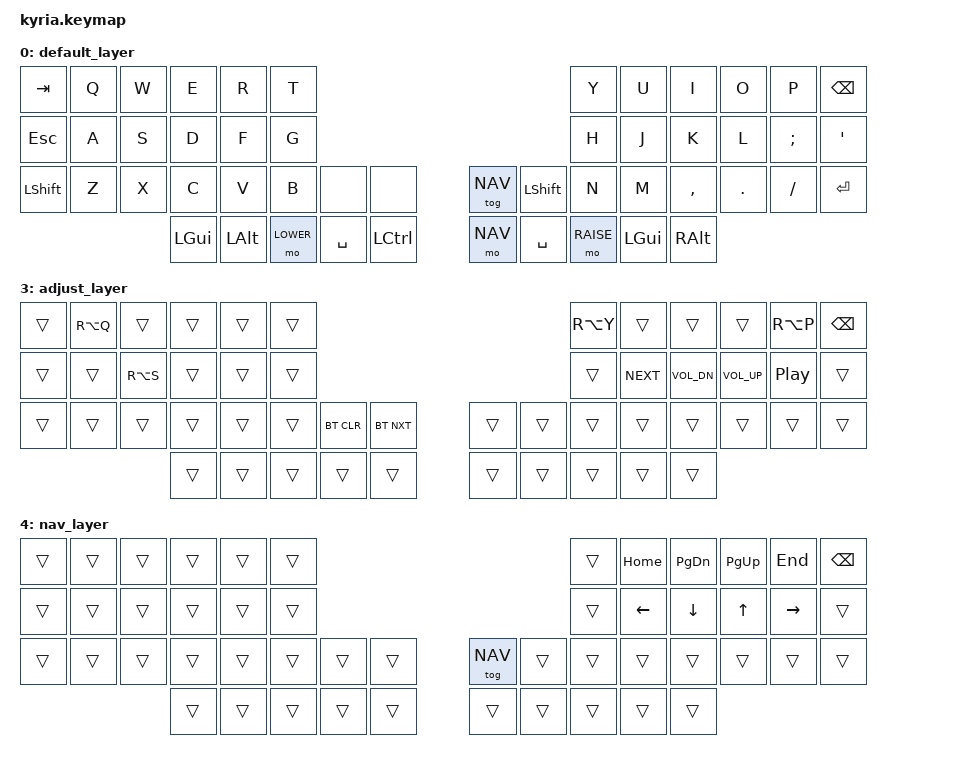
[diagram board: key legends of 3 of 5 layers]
/*
 * Copyright (c) 2020 The ZMK Contributors
 *
 * SPDX-License-Identifier: MIT
 */

#include <behaviors.dtsi>
#include <dt-bindings/zmk/keys.h>
#include <dt-bindings/zmk/bt.h>

#define DEFAULT 0
#define LOWER   1
#define RAISE   2
#define ADJUST  3
#define NAV     4

#define NONE 0

/ {
	conditional_layers {
        compatible = "zmk,conditional-layers";
        tri_layer {
            if-layers = <1 2>;
            then-layer = <3>;
        };
    };
	keymap {
		compatible = "zmk,keymap";

		default_layer {
// ---------------------------------------------------------------------------------------------------------------------------------
// |  ESC  |  Q  |  W  |  E   |  R   |  T   |                                          |  Y   |  U    |  I    |  O   |   P   | BSPC |
//SHIFT/TAB|  A  |  S  |  D   |  F   |  G   |                                          |  H   |  J    |  K    |  L   |   ;   |   '  |
// |  CTRL |  Z  |  X  |  C   |  V   |  B   | L SHIFT | L SHIFT |  |   NAV   | L SHIFT |  N   |  M    |  ,    |  .   |   /   |ENTER |
//                     | CTRL | GUI  | ALT  |  LOWER  |  SPACE  |  |  SPACE  |  RAISE  | TAB  |ADJUST | R-ALT |
			bindings = <
	   &kp TAB &kp Q &kp W &kp E &kp R &kp T                                            &kp Y &kp U  &kp I    &kp O   &kp P    &kp BSPC
       &kp ESC &kp A &kp S &kp D &kp F &kp G                                            &kp H &kp J  &kp K    &kp L   &kp SEMI &kp SQT
     &kp LSHIFT &kp Z &kp X &kp C &kp V &kp B &none &none                  &tog NAV  &kp LSHFT &kp N &kp M  &kp COMMA &kp DOT &kp FSLH &kp RET
	              &kp LGUI &kp LALT &mo LOWER &kp SPACE &kp LCTRL &mo NAV &kp SPACE &mo RAISE &kp LGUI &kp RALT
			>;

			sensor-bindings = <&inc_dec_kp C_VOL_UP C_VOL_DN &inc_dec_kp PG_UP PG_DN>;
		};

		lower_layer {
// ---------------------------------------------------------------------------------------------------------------------------------
// |   ~   |  !  |  @  |  #   |  $   |  %   |                                          |  ^   |  &    |  *    |  (   |   )   |      |
// |  ESC  |  A  |  S  |  D   |  F   |  G   |                                          |  H   |  _    |  +    |  {   |   }   |  |   |
// | SHIFT |  Z  |  X  |  C   |  V   |  B   | L SHIFT | L SHIFT |  |   NAV   | L SHIFT |  N   |  M    |  ,    |  .   |   /   |ENTER |
//                     | CTRL | GUI  | ALT  |  LOWER  |  SPACE  |  |  SPACE  |  RAISE  | TAB  |ADJUST | R-ALT |
			bindings = <
   &kp TILDE &kp EXCL &kp AT &kp HASH &kp DLLR &kp PRCNT                            &kp CARET &kp AMPS &kp ASTRK &kp LPAR &kp RPAR   &kp BSPC
   &kp DEL   &kp F1 &kp F2 &kp F3 &kp F4 &kp F5                                     &kp F6 &kp UNDER &kp PLUS &kp LBRC  &kp RBRC &kp PIPE
   &trans    &kp F7 &kp F8 &kp F9 &kp F10 &kp F11 &none &bt BT_NXT    &tog NAV  &kp LSHFT &kp F12 &kp &trans &kp COMMA &kp DOT &kp FSLH &kp RET
         	             &trans &trans &trans &trans &trans               &trans &trans &trans  &trans  &trans
			>;
		};

		raise_layer {
// ---------------------------------------------------------------------------------------------------------------------------------
// |  TAB  |  1  |  2  |  3   |  4   |  5   |                                          |  6   |  7    |  8    |  9   |   0   |      |
// |  ESC  |  A  |  S  |  D   |  F   |  G   |                                          |  H   |  -    |  =    |  [   |   ]   |  \   |
// | SHIFT |  Z  |  X  |  C   |  V   |  B   | L SHIFT | L SHIFT |  |   NAV   | L SHIFT |  N   |  M    |  ,    |  .   |   /   |ENTER |
//                     | CTRL | GUI  | ALT  |  LOWER  |  SPACE  |  |  SPACE  |  RAISE  | TAB  |ADJUST | R-ALT |
			bindings = <
   &kp GRAVE &kp N1 &kp N2 &kp N3 &kp N4 &kp N5                                       &kp N6 &kp N7  &kp N8    &kp N9   &kp N0  &kp BSPC
   &trans    &kp F1 &kp F2 &kp F3 &kp F4 &kp F5                                       &kp F6 &kp MINUS &kp EQUAL &kp LBKT &kp RBKT &kp BSLH
   &trans    &kp F7 &kp F8 &kp F9 &kp F10 &kp F11 &none &bt BT_NXT    &tog NAV  &kp LSHFT &kp F12 &kp &trans &kp COMMA &kp DOT &kp FSLH &kp RET
         	             &trans &trans &trans &trans &trans               &trans &trans &trans  &trans  &trans
			>;
		};

      	adjust_layer {
// ---------------------------------------------------------------------------------------------------------------------------------
// |       |  ä  |     |      |      |      |                                          |  ü   |       |       |      |   ö   |      |
// |       |     |  ß  |      |      |      |                                          |      |       |       |      |       |      |
// |       |     |     |      |      |      |                                          |      |       |       |      |       |      |
//                     |      |      |      |         |         |  |         |         |      |       |       |
			bindings = <
    &trans &kp RA(Q) &trans &trans &trans &trans                                        &kp RA(Y) &trans  &trans  &trans &kp RA(P) &kp BSPC
    &trans &trans &kp RA(S) &trans &trans &trans                                        &trans  &kp C_NEXT &kp C_VOL_DN  &kp C_VOL_UP &kp C_PLAY_PAUSE &trans
    &trans &trans &trans &trans &trans &trans &bt BT_CLR &bt BT_NXT       &trans &trans &trans  &trans  &trans  &trans &trans &trans
         	             &trans &trans &trans &trans &trans               &trans &trans &trans  &trans  &trans
			>;
		};

    	nav_layer {
// ---------------------------------------------------------------------------------------------------------------------------------
// |       |     |     |      |      |      |                                          |      |       |       |      |       |      |
// |       |     |     |      |      |      |                                          |      |       |       |      |       |      |
// |       |     |     |      |      |      |                                          |      |       |       |      |       |      |
//                     |      |      |      |         |         |  |         |         |      |       |       |
			bindings = <
    &trans &trans &trans &trans &trans &trans                                           &trans  &kp HOME &kp PG_DN &kp PG_UP &kp END &kp BSPC
    &trans &trans &trans &trans &trans &trans                                           &trans  &kp LEFT &kp DOWN &kp UP    &kp RIGHT   &trans
    &trans &trans &trans &trans &trans &trans &trans &trans               &tog NAV &trans &trans  &trans   &trans   &trans    &trans      &trans
         	             &trans &trans &trans &trans &trans               &trans &trans &trans  &trans  &trans
			>;
		};



//    	empty_layer {
// ---------------------------------------------------------------------------------------------------------------------------------
// |       |     |     |      |      |      |                                          |      |       |       |      |       |      |
// |       |     |     |      |      |      |                                          |      |       |       |      |       |      |
// |       |     |     |      |      |      |                                          |      |       |       |      |       |      |
//                     |      |      |      |         |         |  |         |         |      |       |       |
//			bindings = <
//    &trans &trans &trans &trans &trans &trans                                           &trans  &trans  &trans  &trans &trans &trans
//    &trans &trans &trans &trans &trans &trans                                           &trans  &trans  &trans  &trans &trans &trans
//    &trans &trans &trans &trans &trans &trans &trans &trans               &trans &trans &trans  &trans  &trans  &trans &trans &trans
//         	             &trans &trans &trans &trans &trans               &trans &trans &trans  &trans  &trans
//			>;
//		};
	};
};
